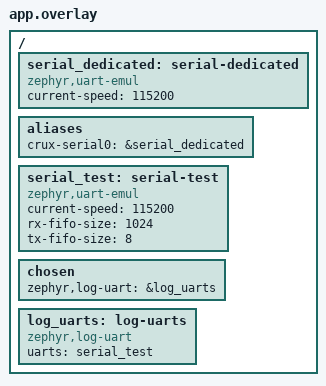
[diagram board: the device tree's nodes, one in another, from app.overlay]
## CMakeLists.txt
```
cmake_minimum_required(VERSION 3.28)
find_package(Zephyr REQUIRED HINTS $ENV{ZEPHYR_BASE})
project(crux_serial_ownership C)
target_sources(app PRIVATE src/main.c)
target_link_libraries(app PRIVATE crux::serial)
```

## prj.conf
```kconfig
CONFIG_ZTEST=y
CONFIG_CRUX_TIME=n
CONFIG_CRUX_SERIAL=y
CONFIG_SERIAL=y
CONFIG_UART_INTERRUPT_DRIVEN=y
CONFIG_UART_USE_RUNTIME_CONFIGURE=y
CONFIG_EMUL=y
CONFIG_UART_EMUL=y
CONFIG_MAIN_STACK_SIZE=4096
CONFIG_TEST_EXTRA_STACK_SIZE=2048
CONFIG_IRQ_OFFLOAD=y
CONFIG_SYS_CLOCK_TICKS_PER_SEC=1000
CONFIG_LOG=y
CONFIG_LOG_BACKEND_UART=y
```

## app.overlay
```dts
/ {
    serial_dedicated: serial-dedicated {
        compatible = "zephyr,uart-emul";
        current-speed = <115200>;
        status = "okay";
    };
    aliases { crux-serial0 = &serial_dedicated; };
    serial_test: serial-test {
        compatible = "zephyr,uart-emul";
        current-speed = <115200>;
        rx-fifo-size = <1024>;
        tx-fifo-size = <8>;
        status = "okay";
    };
};
/ {
    chosen { zephyr,log-uart = &log_uarts; };
    log_uarts: log-uarts { compatible = "zephyr,log-uart"; uarts = <&serial_test>; };
};
```

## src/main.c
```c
#include <crux/serial.h>
#include <zephyr/drivers/uart.h>
#include <zephyr/ztest.h>
ZTEST(serial_ownership, test_dedicated_uart_preserves_logging_owner)
{
    const struct device *dev = DEVICE_DT_GET(DT_NODELABEL(serial_test));
    struct uart_config before, after;
    zassert_ok(uart_config_get(dev, &before));
    crux_serial_config_t requested = {9600, 7, 2, CRUX_SERIAL_PARITY_EVEN};
    crux_serial_t handle;
    crux_status_t result = crux_serial_open(0, &requested, &handle);
    zassert_equal(result, CRUX_OK);
    zassert_ok(crux_serial_close(&handle));
    zassert_ok(uart_config_get(dev, &after));
    zassert_equal(before.baudrate, after.baudrate);
    zassert_equal(before.data_bits, after.data_bits);
}
ZTEST_SUITE(serial_ownership, NULL, NULL, NULL, NULL, NULL);
```
